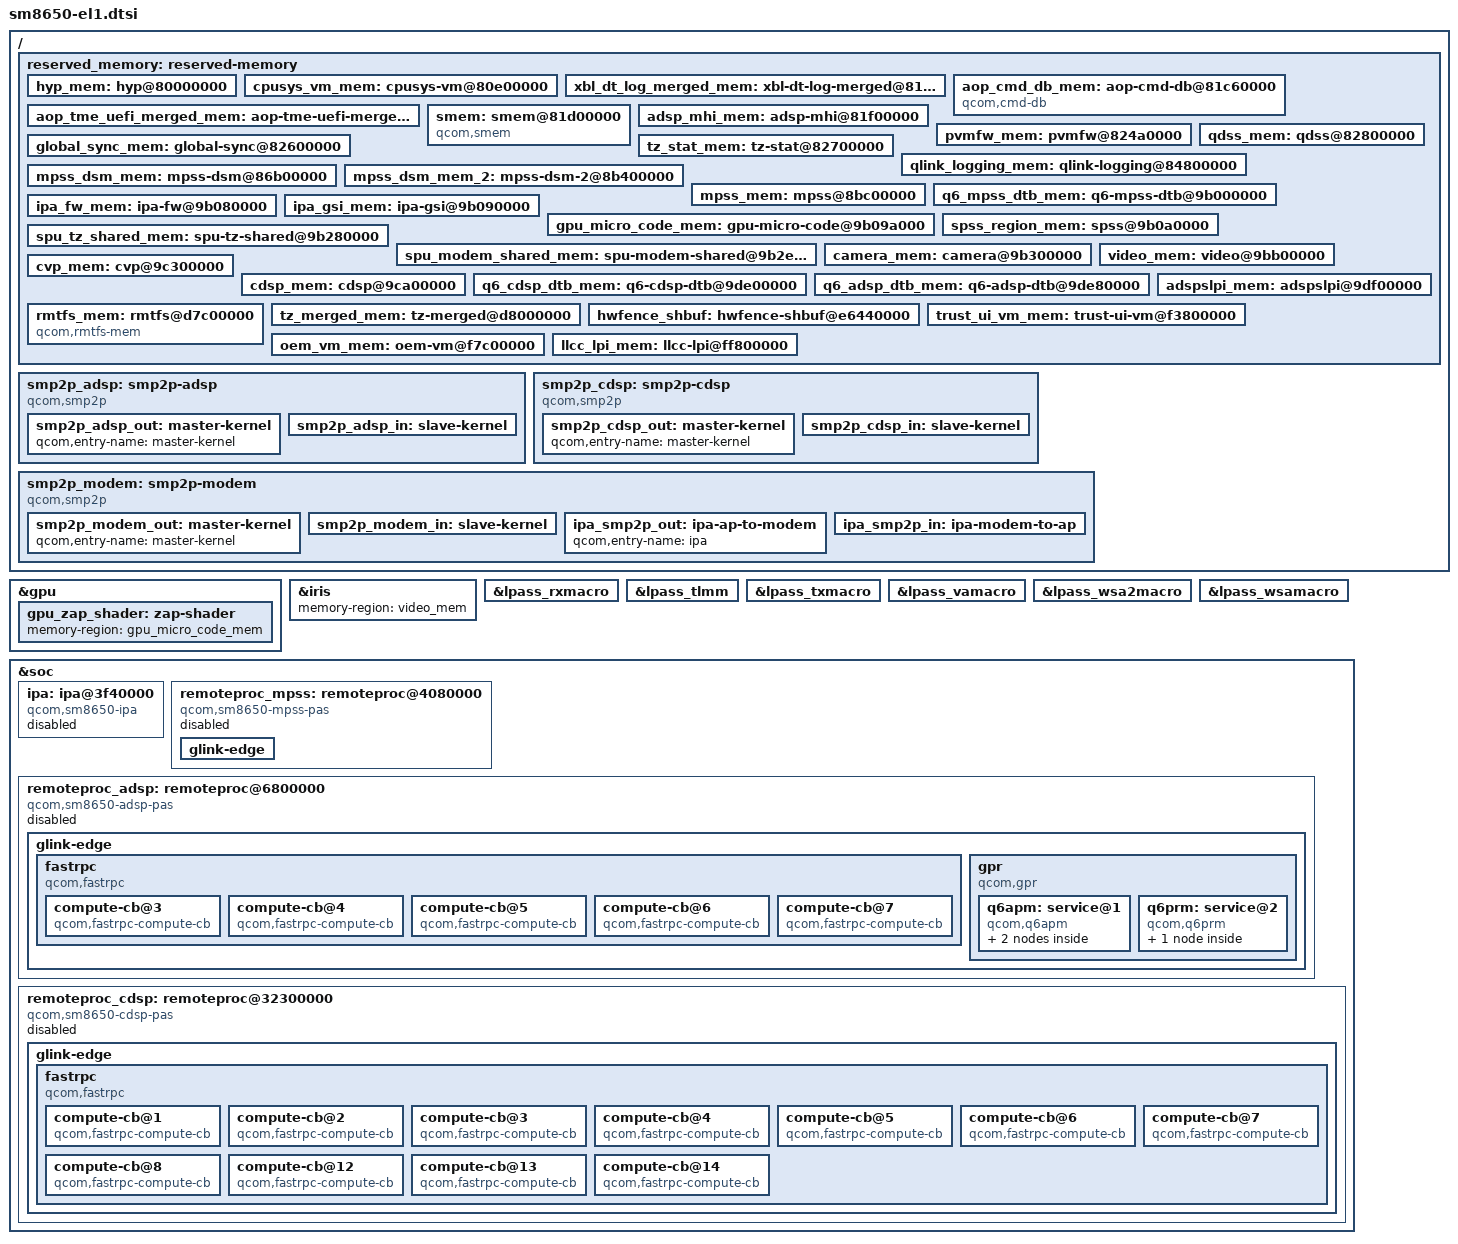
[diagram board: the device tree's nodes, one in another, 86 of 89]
// SPDX-License-Identifier: BSD-3-Clause
/*
 * Copyright (c) 2026, Linaro Limited
 */

#include <dt-bindings/sound/qcom,q6dsp-lpass-ports.h>

/ {
	reserved_memory: reserved-memory {
		#address-cells = <2>;
		#size-cells = <2>;
		ranges;

		hyp_mem: hyp@80000000 {
			reg = <0 0x80000000 0 0xe00000>;
			no-map;
		};

		cpusys_vm_mem: cpusys-vm@80e00000 {
			reg = <0 0x80e00000 0 0x400000>;
			no-map;
		};

		/* Merged xbl_dtlog, xbl_ramdump and aop_image regions */
		xbl_dt_log_merged_mem: xbl-dt-log-merged@81a00000 {
			reg = <0 0x81a00000 0 0x260000>;
			no-map;
		};

		aop_cmd_db_mem: aop-cmd-db@81c60000 {
			compatible = "qcom,cmd-db";
			reg = <0 0x81c60000 0 0x20000>;
			no-map;
		};

		/* Merged aop_config, tme_crash_dump, tme_log, uefi_log, and chipinfo regions */
		aop_tme_uefi_merged_mem: aop-tme-uefi-merged@81c80000 {
			reg = <0 0x81c80000 0 0x75000>;
			no-map;
		};

		/* Secdata region can be reused by apps */

		smem: smem@81d00000 {
			compatible = "qcom,smem";
			reg = <0 0x81d00000 0 0x200000>;
			hwlocks = <&tcsr_mutex 3>;
			no-map;
		};

		adsp_mhi_mem: adsp-mhi@81f00000 {
			reg = <0 0x81f00000 0 0x20000>;
			no-map;
		};

		pvmfw_mem: pvmfw@824a0000 {
			reg = <0 0x824a0000 0 0x100000>;
			no-map;
		};

		global_sync_mem: global-sync@82600000 {
			reg = <0 0x82600000 0 0x100000>;
			no-map;
		};

		tz_stat_mem: tz-stat@82700000 {
			reg = <0 0x82700000 0 0x100000>;
			no-map;
		};

		qdss_mem: qdss@82800000 {
			reg = <0 0x82800000 0 0x2000000>;
			no-map;
		};

		qlink_logging_mem: qlink-logging@84800000 {
			reg = <0 0x84800000 0 0x200000>;
			no-map;
		};

		mpss_dsm_mem: mpss-dsm@86b00000 {
			reg = <0 0x86b00000 0 0x4900000>;
			no-map;
		};

		mpss_dsm_mem_2: mpss-dsm-2@8b400000 {
			reg = <0 0x8b400000 0 0x800000>;
			no-map;
		};

		mpss_mem: mpss@8bc00000 {
			reg = <0 0x8bc00000 0 0xf400000>;
			no-map;
		};

		q6_mpss_dtb_mem: q6-mpss-dtb@9b000000 {
			reg = <0 0x9b000000 0 0x80000>;
			no-map;
		};

		ipa_fw_mem: ipa-fw@9b080000 {
			reg = <0 0x9b080000 0 0x10000>;
			no-map;
		};

		ipa_gsi_mem: ipa-gsi@9b090000 {
			reg = <0 0x9b090000 0 0xa000>;
			no-map;
		};

		gpu_micro_code_mem: gpu-micro-code@9b09a000 {
			reg = <0 0x9b09a000 0 0x2000>;
			no-map;
		};

		spss_region_mem: spss@9b0a0000 {
			reg = <0 0x9b0a0000 0 0x1e0000>;
			no-map;
		};

		/* First part of the "SPU secure shared memory" region */
		spu_tz_shared_mem: spu-tz-shared@9b280000 {
			reg = <0 0x9b280000 0 0x60000>;
			no-map;
		};

		/* Second part of the "SPU secure shared memory" region */
		spu_modem_shared_mem: spu-modem-shared@9b2e0000 {
			reg = <0 0x9b2e0000 0 0x20000>;
			no-map;
		};

		camera_mem: camera@9b300000 {
			reg = <0 0x9b300000 0 0x800000>;
			no-map;
		};

		video_mem: video@9bb00000 {
			reg = <0 0x9bb00000 0 0x800000>;
			no-map;
		};

		cvp_mem: cvp@9c300000 {
			reg = <0 0x9c300000 0 0x700000>;
			no-map;
		};

		cdsp_mem: cdsp@9ca00000 {
			reg = <0 0x9ca00000 0 0x1400000>;
			no-map;
		};

		q6_cdsp_dtb_mem: q6-cdsp-dtb@9de00000 {
			reg = <0 0x9de00000 0 0x80000>;
			no-map;
		};

		q6_adsp_dtb_mem: q6-adsp-dtb@9de80000 {
			reg = <0 0x9de80000 0 0x80000>;
			no-map;
		};

		adspslpi_mem: adspslpi@9df00000 {
			reg = <0 0x9df00000 0 0x4080000>;
			no-map;
		};

		rmtfs_mem: rmtfs@d7c00000 {
			compatible = "qcom,rmtfs-mem";
			reg = <0 0xd7c00000 0 0x400000>;
			no-map;

			qcom,client-id = <1>;
			qcom,vmid = <QCOM_SCM_VMID_MSS_MSA>;
		};

		/* Merged tz_reserved, xbl_sc, cpucp_fw and qtee regions */
		tz_merged_mem: tz-merged@d8000000 {
			reg = <0 0xd8000000 0 0x800000>;
			no-map;
		};

		hwfence_shbuf: hwfence-shbuf@e6440000 {
			reg = <0 0xe6440000 0 0x2dd000>;
			no-map;
		};

		trust_ui_vm_mem: trust-ui-vm@f3800000 {
			reg = <0 0xf3800000 0 0x4400000>;
			no-map;
		};

		oem_vm_mem: oem-vm@f7c00000 {
			reg = <0 0xf7c00000 0 0x4c00000>;
			no-map;
		};

		llcc_lpi_mem: llcc-lpi@ff800000 {
			reg = <0 0xff800000 0 0x600000>;
			no-map;
		};
	};

	smp2p_adsp: smp2p-adsp {
		compatible = "qcom,smp2p";

		interrupts-extended = <&ipcc IPCC_CLIENT_LPASS
					     IPCC_MPROC_SIGNAL_SMP2P
					     IRQ_TYPE_EDGE_RISING>;

		mboxes = <&ipcc IPCC_CLIENT_LPASS
				IPCC_MPROC_SIGNAL_SMP2P>;

		qcom,smem = <443>, <429>;
		qcom,local-pid = <0>;
		qcom,remote-pid = <2>;

		smp2p_adsp_out: master-kernel {
			qcom,entry-name = "master-kernel";
			#qcom,smem-state-cells = <1>;
		};

		smp2p_adsp_in: slave-kernel {
			qcom,entry-name = "slave-kernel";
			interrupt-controller;
			#interrupt-cells = <2>;
		};
	};

	smp2p_cdsp: smp2p-cdsp {
		compatible = "qcom,smp2p";

		interrupts-extended = <&ipcc IPCC_CLIENT_CDSP
					     IPCC_MPROC_SIGNAL_SMP2P
					     IRQ_TYPE_EDGE_RISING>;

		mboxes = <&ipcc IPCC_CLIENT_CDSP
				IPCC_MPROC_SIGNAL_SMP2P>;

		qcom,smem = <94>, <432>;
		qcom,local-pid = <0>;
		qcom,remote-pid = <5>;

		smp2p_cdsp_out: master-kernel {
			qcom,entry-name = "master-kernel";
			#qcom,smem-state-cells = <1>;
		};

		smp2p_cdsp_in: slave-kernel {
			qcom,entry-name = "slave-kernel";
			interrupt-controller;
			#interrupt-cells = <2>;
		};
	};

	smp2p_modem: smp2p-modem {
		compatible = "qcom,smp2p";

		interrupts-extended = <&ipcc IPCC_CLIENT_MPSS
					     IPCC_MPROC_SIGNAL_SMP2P
					     IRQ_TYPE_EDGE_RISING>;

		mboxes = <&ipcc IPCC_CLIENT_MPSS
				IPCC_MPROC_SIGNAL_SMP2P>;

		qcom,smem = <435>, <428>;
		qcom,local-pid = <0>;
		qcom,remote-pid = <1>;

		smp2p_modem_out: master-kernel {
			qcom,entry-name = "master-kernel";
			#qcom,smem-state-cells = <1>;
		};

		smp2p_modem_in: slave-kernel {
			qcom,entry-name = "slave-kernel";
			interrupt-controller;
			#interrupt-cells = <2>;
		};

		ipa_smp2p_out: ipa-ap-to-modem {
			qcom,entry-name = "ipa";
			#qcom,smem-state-cells = <1>;
		};

		ipa_smp2p_in: ipa-modem-to-ap {
			qcom,entry-name = "ipa";
			interrupt-controller;
			#interrupt-cells = <2>;
		};
	};
};

&gpu {
	gpu_zap_shader: zap-shader {
		memory-region = <&gpu_micro_code_mem>;
	};
};

&iris {
	memory-region = <&video_mem>;
};

&lpass_rxmacro {
	clocks = <&q6prmcc LPASS_CLK_ID_RX_CORE_TX_MCLK LPASS_CLK_ATTRIBUTE_COUPLE_NO>,
		 <&q6prmcc LPASS_HW_MACRO_VOTE LPASS_CLK_ATTRIBUTE_COUPLE_NO>,
		 <&q6prmcc LPASS_HW_DCODEC_VOTE LPASS_CLK_ATTRIBUTE_COUPLE_NO>,
		 <&lpass_vamacro>;
	status = "okay";
};

&lpass_tlmm {
	clocks = <&q6prmcc LPASS_HW_MACRO_VOTE LPASS_CLK_ATTRIBUTE_COUPLE_NO>,
		 <&q6prmcc LPASS_HW_DCODEC_VOTE LPASS_CLK_ATTRIBUTE_COUPLE_NO>;
	status = "okay";
};

&lpass_txmacro {
	clocks = <&q6prmcc LPASS_CLK_ID_TX_CORE_MCLK LPASS_CLK_ATTRIBUTE_COUPLE_NO>,
		 <&q6prmcc LPASS_HW_MACRO_VOTE LPASS_CLK_ATTRIBUTE_COUPLE_NO>,
		 <&q6prmcc LPASS_HW_DCODEC_VOTE LPASS_CLK_ATTRIBUTE_COUPLE_NO>,
		 <&lpass_vamacro>;
	status = "okay";
};

&lpass_vamacro {
	clocks = <&q6prmcc LPASS_CLK_ID_TX_CORE_MCLK LPASS_CLK_ATTRIBUTE_COUPLE_NO>,
		 <&q6prmcc LPASS_HW_MACRO_VOTE LPASS_CLK_ATTRIBUTE_COUPLE_NO>,
		 <&q6prmcc LPASS_HW_DCODEC_VOTE LPASS_CLK_ATTRIBUTE_COUPLE_NO>;
	clock-names = "mclk",
		      "macro",
		      "dcodec";
	status = "okay";
};

&lpass_wsa2macro {
	clocks = <&q6prmcc LPASS_CLK_ID_WSA2_CORE_TX_MCLK LPASS_CLK_ATTRIBUTE_COUPLE_NO>,
		 <&q6prmcc LPASS_HW_MACRO_VOTE LPASS_CLK_ATTRIBUTE_COUPLE_NO>,
		 <&q6prmcc LPASS_HW_DCODEC_VOTE LPASS_CLK_ATTRIBUTE_COUPLE_NO>,
		 <&lpass_vamacro>;
	status = "okay";
};

&lpass_wsamacro {
	clocks = <&q6prmcc LPASS_CLK_ID_WSA_CORE_TX_MCLK LPASS_CLK_ATTRIBUTE_COUPLE_NO>,
		 <&q6prmcc LPASS_HW_MACRO_VOTE LPASS_CLK_ATTRIBUTE_COUPLE_NO>,
		 <&q6prmcc LPASS_HW_DCODEC_VOTE LPASS_CLK_ATTRIBUTE_COUPLE_NO>,
		 <&lpass_vamacro>;
	status = "okay";
};

&soc {
	ipa: ipa@3f40000 {
		compatible = "qcom,sm8650-ipa", "qcom,sm8550-ipa";

		iommus = <&apps_smmu 0x4a0 0x0>,
			 <&apps_smmu 0x4a2 0x0>;
		reg = <0 0x3f40000 0 0x10000>,
		      <0 0x3f50000 0 0x5000>,
		      <0 0x3e04000 0 0xfc000>;
		reg-names = "ipa-reg",
			    "ipa-shared",
			    "gsi";

		interrupts-extended = <&intc GIC_SPI 654 IRQ_TYPE_EDGE_RISING 0>,
				      <&intc GIC_SPI 432 IRQ_TYPE_LEVEL_HIGH 0>,
				      <&ipa_smp2p_in 0 IRQ_TYPE_EDGE_RISING>,
				      <&ipa_smp2p_in 1 IRQ_TYPE_EDGE_RISING>;
		interrupt-names = "ipa",
				  "gsi",
				  "ipa-clock-query",
				  "ipa-setup-ready";

		clocks = <&rpmhcc RPMH_IPA_CLK>;
		clock-names = "core";

		interconnects = <&aggre2_noc MASTER_IPA QCOM_ICC_TAG_ALWAYS
				 &mc_virt SLAVE_EBI1 QCOM_ICC_TAG_ALWAYS>,
				<&gem_noc MASTER_APPSS_PROC QCOM_ICC_TAG_ACTIVE_ONLY
				 &config_noc SLAVE_IPA_CFG QCOM_ICC_TAG_ACTIVE_ONLY>;
		interconnect-names = "memory",
				     "config";

		qcom,qmp = <&aoss_qmp>;

		qcom,smem-states = <&ipa_smp2p_out 0>,
				   <&ipa_smp2p_out 1>;
		qcom,smem-state-names = "ipa-clock-enabled-valid",
					"ipa-clock-enabled";

		qcom,gsi-loader = "self";
		memory-region = <&ipa_fw_mem>;

		sram = <&ipa_modem_tables>;

		status = "disabled";
	};

	remoteproc_mpss: remoteproc@4080000 {
		compatible = "qcom,sm8650-mpss-pas";
		reg = <0x0 0x04080000 0x0 0x10000>;

		interrupts-extended = <&intc GIC_SPI 264 IRQ_TYPE_EDGE_RISING 0>,
				      <&smp2p_modem_in 0 IRQ_TYPE_EDGE_RISING>,
				      <&smp2p_modem_in 1 IRQ_TYPE_EDGE_RISING>,
				      <&smp2p_modem_in 2 IRQ_TYPE_EDGE_RISING>,
				      <&smp2p_modem_in 3 IRQ_TYPE_EDGE_RISING>,
				      <&smp2p_modem_in 7 IRQ_TYPE_EDGE_RISING>;
		interrupt-names = "wdog",
				  "fatal",
				  "ready",
				  "handover",
				  "stop-ack",
				  "shutdown-ack";

		clocks = <&rpmhcc RPMH_CXO_CLK>;
		clock-names = "xo";

		interconnects = <&mc_virt MASTER_LLCC QCOM_ICC_TAG_ALWAYS
				 &mc_virt SLAVE_EBI1 QCOM_ICC_TAG_ALWAYS>;

		power-domains = <&rpmhpd RPMHPD_CX>,
				<&rpmhpd RPMHPD_MSS>;
		power-domain-names = "cx",
				     "mss";

		memory-region = <&mpss_mem>, <&q6_mpss_dtb_mem>,
				<&mpss_dsm_mem>, <&mpss_dsm_mem_2>,
				<&qlink_logging_mem>;

		qcom,qmp = <&aoss_qmp>;

		qcom,smem-states = <&smp2p_modem_out 0>;
		qcom,smem-state-names = "stop";

		status = "disabled";

		glink-edge {
			interrupts-extended = <&ipcc IPCC_CLIENT_MPSS
						     IPCC_MPROC_SIGNAL_GLINK_QMP
						     IRQ_TYPE_EDGE_RISING>;

			mboxes = <&ipcc IPCC_CLIENT_MPSS
					IPCC_MPROC_SIGNAL_GLINK_QMP>;

			qcom,remote-pid = <1>;

			label = "mpss";
		};
	};

	remoteproc_adsp: remoteproc@6800000 {
		compatible = "qcom,sm8650-adsp-pas";
		reg = <0x0 0x06800000 0x0 0x10000>;

		interrupts-extended = <&pdc 6 IRQ_TYPE_EDGE_RISING>,
				      <&smp2p_adsp_in 0 IRQ_TYPE_EDGE_RISING>,
				      <&smp2p_adsp_in 1 IRQ_TYPE_EDGE_RISING>,
				      <&smp2p_adsp_in 2 IRQ_TYPE_EDGE_RISING>,
				      <&smp2p_adsp_in 3 IRQ_TYPE_EDGE_RISING>;
		interrupt-names = "wdog",
				  "fatal",
				  "ready",
				  "handover",
				  "stop-ack";

		clocks = <&rpmhcc RPMH_CXO_CLK>;
		clock-names = "xo";

		interconnects = <&lpass_lpicx_noc MASTER_LPASS_PROC QCOM_ICC_TAG_ALWAYS
				 &mc_virt SLAVE_EBI1 QCOM_ICC_TAG_ALWAYS>;

		power-domains = <&rpmhpd RPMHPD_LCX>,
				<&rpmhpd RPMHPD_LMX>;
		power-domain-names = "lcx",
				     "lmx";

		memory-region = <&adspslpi_mem>, <&q6_adsp_dtb_mem>;

		qcom,qmp = <&aoss_qmp>;

		qcom,smem-states = <&smp2p_adsp_out 0>;
		qcom,smem-state-names = "stop";

		status = "disabled";

		glink-edge {
			interrupts-extended = <&ipcc IPCC_CLIENT_LPASS
						     IPCC_MPROC_SIGNAL_GLINK_QMP
						     IRQ_TYPE_EDGE_RISING>;

			mboxes = <&ipcc IPCC_CLIENT_LPASS
					IPCC_MPROC_SIGNAL_GLINK_QMP>;

			qcom,remote-pid = <2>;

			label = "lpass";

			fastrpc {
				compatible = "qcom,fastrpc";

				qcom,glink-channels = "fastrpcglink-apps-dsp";

				label = "adsp";

				qcom,non-secure-domain;

				#address-cells = <1>;
				#size-cells = <0>;

				compute-cb@3 {
					compatible = "qcom,fastrpc-compute-cb";
					reg = <3>;

					iommus = <&apps_smmu 0x1003 0x80>,
						 <&apps_smmu 0x1043 0x20>;
					dma-coherent;
				};

				compute-cb@4 {
					compatible = "qcom,fastrpc-compute-cb";
					reg = <4>;

					iommus = <&apps_smmu 0x1004 0x80>,
						 <&apps_smmu 0x1044 0x20>;
					dma-coherent;
				};

				compute-cb@5 {
					compatible = "qcom,fastrpc-compute-cb";
					reg = <5>;

					iommus = <&apps_smmu 0x1005 0x80>,
						 <&apps_smmu 0x1045 0x20>;
					dma-coherent;
				};

				compute-cb@6 {
					compatible = "qcom,fastrpc-compute-cb";
					reg = <6>;

					iommus = <&apps_smmu 0x1006 0x80>,
						 <&apps_smmu 0x1046 0x20>;
					dma-coherent;
				};

				compute-cb@7 {
					compatible = "qcom,fastrpc-compute-cb";
					reg = <7>;

					iommus = <&apps_smmu 0x1007 0x40>,
						 <&apps_smmu 0x1067 0x0>,
						 <&apps_smmu 0x1087 0x0>;
					dma-coherent;
				};
			};

			gpr {
				compatible = "qcom,gpr";
				qcom,glink-channels = "adsp_apps";
				qcom,domain = <GPR_DOMAIN_ID_ADSP>;
				qcom,intents = <512 20>;
				#address-cells = <1>;
				#size-cells = <0>;

				q6apm: service@1 {
					compatible = "qcom,q6apm";
					reg = <GPR_APM_MODULE_IID>;
					#sound-dai-cells = <0>;
					qcom,protection-domain = "avs/audio",
								 "msm/adsp/audio_pd";

					q6apmbedai: bedais {
						compatible = "qcom,q6apm-lpass-dais";
						#sound-dai-cells = <1>;
					};

					q6apmdai: dais {
						compatible = "qcom,q6apm-dais";
						iommus = <&apps_smmu 0x1001 0x80>,
							 <&apps_smmu 0x1061 0x0>;
					};
				};

				q6prm: service@2 {
					compatible = "qcom,q6prm";
					reg = <GPR_PRM_MODULE_IID>;
					qcom,protection-domain = "avs/audio",
								 "msm/adsp/audio_pd";

					q6prmcc: clock-controller {
						compatible = "qcom,q6prm-lpass-clocks";
						#clock-cells = <2>;
					};
				};
			};
		};
	};

	remoteproc_cdsp: remoteproc@32300000 {
		compatible = "qcom,sm8650-cdsp-pas";
		reg = <0x0 0x32300000 0x0 0x10000>;

		interrupts-extended = <&intc GIC_SPI 578 IRQ_TYPE_EDGE_RISING 0>,
				      <&smp2p_cdsp_in 0 IRQ_TYPE_EDGE_RISING>,
				      <&smp2p_cdsp_in 1 IRQ_TYPE_EDGE_RISING>,
				      <&smp2p_cdsp_in 2 IRQ_TYPE_EDGE_RISING>,
				      <&smp2p_cdsp_in 3 IRQ_TYPE_EDGE_RISING>;
		interrupt-names = "wdog",
				  "fatal",
				  "ready",
				  "handover",
				  "stop-ack";

		clocks = <&rpmhcc RPMH_CXO_CLK>;
		clock-names = "xo";

		interconnects = <&nsp_noc MASTER_CDSP_PROC QCOM_ICC_TAG_ALWAYS
				 &mc_virt SLAVE_EBI1 QCOM_ICC_TAG_ALWAYS>;

		power-domains = <&rpmhpd RPMHPD_CX>,
				<&rpmhpd RPMHPD_MXC>,
				<&rpmhpd RPMHPD_NSP>;
		power-domain-names = "cx",
				     "mxc",
				     "nsp";

		memory-region = <&cdsp_mem>, <&q6_cdsp_dtb_mem>, <&global_sync_mem>;

		qcom,qmp = <&aoss_qmp>;

		qcom,smem-states = <&smp2p_cdsp_out 0>;
		qcom,smem-state-names = "stop";

		status = "disabled";

		glink-edge {
			interrupts-extended = <&ipcc IPCC_CLIENT_CDSP
						     IPCC_MPROC_SIGNAL_GLINK_QMP
						     IRQ_TYPE_EDGE_RISING>;

			mboxes = <&ipcc IPCC_CLIENT_CDSP
					IPCC_MPROC_SIGNAL_GLINK_QMP>;

			qcom,remote-pid = <5>;

			label = "cdsp";

			fastrpc {
				compatible = "qcom,fastrpc";

				qcom,glink-channels = "fastrpcglink-apps-dsp";

				label = "cdsp";

				qcom,non-secure-domain;

				#address-cells = <1>;
				#size-cells = <0>;

				compute-cb@1 {
					compatible = "qcom,fastrpc-compute-cb";
					reg = <1>;

					iommus = <&apps_smmu 0x1961 0x0>,
						 <&apps_smmu 0x0c01 0x20>,
						 <&apps_smmu 0x19c1 0x0>;
					dma-coherent;
				};

				compute-cb@2 {
					compatible = "qcom,fastrpc-compute-cb";
					reg = <2>;

					iommus = <&apps_smmu 0x1962 0x0>,
						 <&apps_smmu 0x0c02 0x20>,
						 <&apps_smmu 0x19c2 0x0>;
					dma-coherent;
				};

				compute-cb@3 {
					compatible = "qcom,fastrpc-compute-cb";
					reg = <3>;

					iommus = <&apps_smmu 0x1963 0x0>,
						 <&apps_smmu 0x0c03 0x20>,
						 <&apps_smmu 0x19c3 0x0>;
					dma-coherent;
				};

				compute-cb@4 {
					compatible = "qcom,fastrpc-compute-cb";
					reg = <4>;

					iommus = <&apps_smmu 0x1964 0x0>,
						 <&apps_smmu 0x0c04 0x20>,
						 <&apps_smmu 0x19c4 0x0>;
					dma-coherent;
				};

				compute-cb@5 {
					compatible = "qcom,fastrpc-compute-cb";
					reg = <5>;

					iommus = <&apps_smmu 0x1965 0x0>,
						 <&apps_smmu 0x0c05 0x20>,
						 <&apps_smmu 0x19c5 0x0>;
					dma-coherent;
				};

				compute-cb@6 {
					compatible = "qcom,fastrpc-compute-cb";
					reg = <6>;

					iommus = <&apps_smmu 0x1966 0x0>,
						 <&apps_smmu 0x0c06 0x20>,
						 <&apps_smmu 0x19c6 0x0>;
					dma-coherent;
				};

				compute-cb@7 {
					compatible = "qcom,fastrpc-compute-cb";
					reg = <7>;

					iommus = <&apps_smmu 0x1967 0x0>,
						 <&apps_smmu 0x0c07 0x20>,
						 <&apps_smmu 0x19c7 0x0>;
					dma-coherent;
				};

				compute-cb@8 {
					compatible = "qcom,fastrpc-compute-cb";
					reg = <8>;

					iommus = <&apps_smmu 0x1968 0x0>,
						 <&apps_smmu 0x0c08 0x20>,
						 <&apps_smmu 0x19c8 0x0>;
					dma-coherent;
				};

				/* note: secure cb9 in downstream */

				compute-cb@12 {
					compatible = "qcom,fastrpc-compute-cb";
					reg = <12>;

					iommus = <&apps_smmu 0x196c 0x0>,
						 <&apps_smmu 0x0c0c 0x20>,
						 <&apps_smmu 0x19cc 0x0>;
					dma-coherent;
				};

				compute-cb@13 {
					compatible = "qcom,fastrpc-compute-cb";
					reg = <13>;

					iommus = <&apps_smmu 0x196d 0x0>,
						 <&apps_smmu 0x0c0d 0x20>,
						 <&apps_smmu 0x19cd 0x0>;
					dma-coherent;
				};

				compute-cb@14 {
					compatible = "qcom,fastrpc-compute-cb";
					reg = <14>;

					iommus = <&apps_smmu 0x196e 0x0>,
						 <&apps_smmu 0x0c0e 0x20>,
						 <&apps_smmu 0x19ce 0x0>;
					dma-coherent;
				};
			};
		};
	};
};
